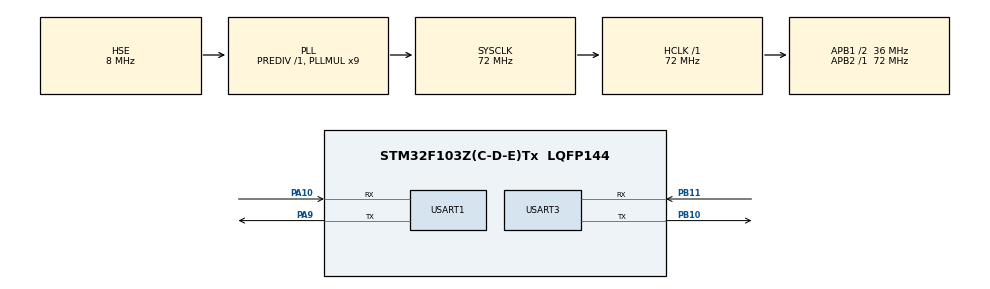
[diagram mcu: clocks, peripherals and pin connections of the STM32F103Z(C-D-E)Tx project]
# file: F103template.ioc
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FREERTOS.Tasks01=defaultTask,24,128,StartDefaultTask,Default,NULL,Dynamic,NULL,NULL
Mcu.Family=STM32F1
Mcu.Name=STM32F103Z(C-D-E)Tx
Mcu.Package=LQFP144
NVIC.PriorityGroup=NVIC_PRIORITYGROUP_4
NVIC.TIM6_IRQn=true\:15\:0\:false\:false\:true\:false\:false\:true
NVIC.TimeBase=TIM6_IRQn
NVIC.TimeBaseIP=TIM6
NVIC.USART1_IRQn=true\:5\:0\:false\:false\:true\:true\:true\:true
NVIC.USART3_IRQn=true\:5\:0\:false\:false\:true\:true\:true\:true
OSC_IN.Mode=HSE-External-Oscillator
OSC_IN.Signal=RCC_OSC_IN
OSC_OUT.Mode=HSE-External-Oscillator
OSC_OUT.Signal=RCC_OSC_OUT
PA10.Mode=Asynchronous
PA10.Signal=USART1_RX
PA13.Mode=Serial_Wire
PA13.Signal=SYS_JTMS-SWDIO
PA14.Mode=Serial_Wire
PA14.Signal=SYS_JTCK-SWCLK
PA9.Mode=Asynchronous
PA9.Signal=USART1_TX
PB10.Mode=Asynchronous
PB10.Signal=USART3_TX
PB11.Mode=Asynchronous
PB11.Signal=USART3_RX
PC14-OSC32_IN.Mode=LSE-External-Oscillator
PC14-OSC32_IN.Signal=RCC_OSC32_IN
PC15-OSC32_OUT.Mode=LSE-External-Oscillator
PC15-OSC32_OUT.Signal=RCC_OSC32_OUT
ProjectManager.HeapSize=0x200
ProjectManager.StackSize=0x400
ProjectManager.TargetToolchain=STM32CubeIDE
RCC.AHBFreq_Value=72000000
RCC.APB1CLKDivider=RCC_HCLK_DIV2
RCC.APB1Freq_Value=36000000
RCC.APB1TimFreq_Value=72000000
RCC.APB2Freq_Value=72000000
RCC.APB2TimFreq_Value=72000000
RCC.HCLKFreq_Value=72000000
RCC.PLLMUL=RCC_PLL_MUL9
RCC.PLLSourceVirtual=RCC_PLLSOURCE_HSE
RCC.RTCClockSelection=RCC_RTCCLKSOURCE_LSE
RCC.SYSCLKFreq_VALUE=72000000
RCC.SYSCLKSource=RCC_SYSCLKSOURCE_PLLCLK
RCC.USBFreq_Value=72000000
USART1.VirtualMode=VM_ASYNC
USART3.VirtualMode=VM_ASYNC
VP_CRC_VS_CRC.Mode=CRC_Activate
VP_FREERTOS_VS_CMSIS_V2.Mode=CMSIS_V2
VP_RTC_VS_RTC_Activate.Mode=RTC_Enabled
VP_RTC_VS_RTC_Calendar.Mode=RTC_Calendar
VP_SYS_VS_tim6.Mode=TIM6
board=custom

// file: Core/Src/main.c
/* USER CODE BEGIN Header */
/**
  ******************************************************************************
  * @file           : main.c
  * @brief          : Main program body
  ******************************************************************************
  * @attention
  *
  * <h2><center>&copy; Copyright (c) 2024 STMicroelectronics.
  * All rights reserved.</center></h2>
  *
  * This software component is licensed by ST under Ultimate Liberty license
  * SLA0044, the "License"; You may not use this file except in compliance with
  * the License. You may obtain a copy of the License at:
  *                             www.st.com/SLA0044
  *
  ******************************************************************************
  */
/* USER CODE END Header */
#include "main.h"
#include "cmsis_os.h"
#include "crc.h"
#include "rtc.h"
#include "usart.h"
#include "gpio.h"

void SystemClock_Config(void);
void MX_FREERTOS_Init(void);

int main(void)
{

  /* MCU Configuration--------------------------------------------------------*/

  /* Reset of all peripherals, Initializes the Flash interface and the Systick. */
  HAL_Init();

  /* Configure the system clock */
  SystemClock_Config();

  /* Initialize all configured peripherals */
  MX_GPIO_Init();
  MX_CRC_Init();
  MX_RTC_Init();
  MX_USART1_UART_Init();
  MX_USART3_UART_Init();

  /* Init scheduler */
  osKernelInitialize();  /* Call init function for freertos objects (in freertos.c) */
  MX_FREERTOS_Init();
  /* Start scheduler */
  osKernelStart();

  /* We should never get here as control is now taken by the scheduler */
  /* Infinite loop */
  while (1)
  {

  }
}

void SystemClock_Config(void)
{
  RCC_OscInitTypeDef RCC_OscInitStruct = {0};
  RCC_ClkInitTypeDef RCC_ClkInitStruct = {0};
  RCC_PeriphCLKInitTypeDef PeriphClkInit = {0};

  /** Initializes the RCC Oscillators according to the specified parameters
  * in the RCC_OscInitTypeDef structure.
  */
  RCC_OscInitStruct.OscillatorType = RCC_OSCILLATORTYPE_HSE|RCC_OSCILLATORTYPE_LSE;
  RCC_OscInitStruct.HSEState = RCC_HSE_ON;
  RCC_OscInitStruct.HSEPredivValue = RCC_HSE_PREDIV_DIV1;
  RCC_OscInitStruct.LSEState = RCC_LSE_ON;
  RCC_OscInitStruct.HSIState = RCC_HSI_ON;
  RCC_OscInitStruct.PLL.PLLState = RCC_PLL_ON;
  RCC_OscInitStruct.PLL.PLLSource = RCC_PLLSOURCE_HSE;
  RCC_OscInitStruct.PLL.PLLMUL = RCC_PLL_MUL9;
  if (HAL_RCC_OscConfig(&RCC_OscInitStruct) != HAL_OK)
  {
    Error_Handler();
  }
  /** Initializes the CPU, AHB and APB buses clocks
  */
  RCC_ClkInitStruct.ClockType = RCC_CLOCKTYPE_HCLK|RCC_CLOCKTYPE_SYSCLK
                              |RCC_CLOCKTYPE_PCLK1|RCC_CLOCKTYPE_PCLK2;
  RCC_ClkInitStruct.SYSCLKSource = RCC_SYSCLKSOURCE_PLLCLK;
  RCC_ClkInitStruct.AHBCLKDivider = RCC_SYSCLK_DIV1;
  RCC_ClkInitStruct.APB1CLKDivider = RCC_HCLK_DIV2;
  RCC_ClkInitStruct.APB2CLKDivider = RCC_HCLK_DIV1;

  if (HAL_RCC_ClockConfig(&RCC_ClkInitStruct, FLASH_LATENCY_2) != HAL_OK)
  {
    Error_Handler();
  }
  PeriphClkInit.PeriphClockSelection = RCC_PERIPHCLK_RTC;
  PeriphClkInit.RTCClockSelection = RCC_RTCCLKSOURCE_LSE;
  if (HAL_RCCEx_PeriphCLKConfig(&PeriphClkInit) != HAL_OK)
  {
    Error_Handler();
  }
}

void HAL_TIM_PeriodElapsedCallback(TIM_HandleTypeDef *htim)
{
  if (htim->Instance == TIM6) {
    HAL_IncTick();
  }
}

void Error_Handler(void)
{
  __disable_irq();
  while (1)
  {
  }
}

/************************ (C) COPYRIGHT STMicroelectronics *****END OF FILE****/

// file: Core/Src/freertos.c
/* USER CODE BEGIN Header */
/**
  ******************************************************************************
  * File Name          : freertos.c
  * Description        : Code for freertos applications
  ******************************************************************************
  * @attention
  *
  * <h2><center>&copy; Copyright (c) 2024 STMicroelectronics.
  * All rights reserved.</center></h2>
  *
  * This software component is licensed by ST under Ultimate Liberty license
  * SLA0044, the "License"; You may not use this file except in compliance with
  * the License. You may obtain a copy of the License at:
  *                             www.st.com/SLA0044
  *
  ******************************************************************************
  */
/* USER CODE END Header */

#include "FreeRTOS.h"
#include "task.h"
#include "main.h"
#include "cmsis_os.h"

/* USER CODE BEGIN Includes */
#include "shell_port.h" //FIXME

/* USER CODE END Includes */

/* Definitions for defaultTask */
osThreadId_t defaultTaskHandle;
const osThreadAttr_t defaultTask_attributes = {
  .name = "defaultTask",
  .stack_size = 128 * 4,
  .priority = (osPriority_t) osPriorityNormal,
};

void StartDefaultTask(void *argument);

void MX_FREERTOS_Init(void); /* (MISRA C 2004 rule 8.1) */

void MX_FREERTOS_Init(void) {

  /* Create the thread(s) */
  /* creation of defaultTask */
  defaultTaskHandle = osThreadNew(StartDefaultTask, NULL, &defaultTask_attributes);

}

void StartDefaultTask(void *argument)
{
  /* USER CODE BEGIN StartDefaultTask */
  userShellInit();

  /* Infinite loop */
  for(;;)
  {
    shellHld();

    osDelay(1);
  }
  /* USER CODE END StartDefaultTask */
}

/************************ (C) COPYRIGHT STMicroelectronics *****END OF FILE****/
